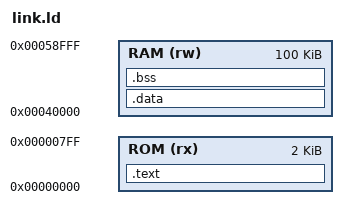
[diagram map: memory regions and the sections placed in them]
ENTRY(_start)

MEMORY
{
    ROM (rx) : ORIGIN = 0x00000000, LENGTH = 2K
    RAM (rw) : ORIGIN = 0x00040000, LENGTH = 100K
}

SECTIONS
{
    .text : {
        *(.text._start)
        *(.text*)
        *(.rodata*)
    } > ROM

    .data : {
        *(.data*)
    } > RAM

    .bss : {
        *(.bss*)
    } > RAM
}
